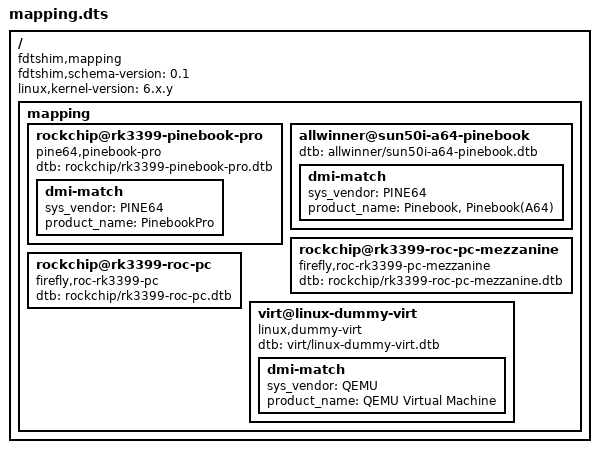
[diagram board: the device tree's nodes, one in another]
/dts-v1/;

/ {
	fdtshim,schema-version = "0.1";
	compatible = "fdtshim,mapping";
	linux,kernel-version = "6.x.y"; // metadata for convenience...
	// TODO: see what other metadata could be added...
	mapping {
		// Prop names are arbitrary, but should match the dtb path scheme.
		// `$vendor/$board.dtb` → `$vendor@$board`
		rockchip@rk3399-pinebook-pro {
			dtb = "rockchip/rk3399-pinebook-pro.dtb";
			// Compatible string should be the root compatible string of the device.
			// TODO: define what to do for devices with conflated compatible names.
			compatible = "pine64,pinebook-pro";
			dmi-match {
				// All of those entries would be good matches
				// The two first ones would be preferred and sufficient.
				sys_vendor = "PINE64";
				product_name = "PinebookPro";

			};
		};
		allwinner@sun50i-a64-pinebook {
			dtb = "allwinner/sun50i-a64-pinebook.dtb";
			// compatible = "pine64,pinebook"; // Commented-out for testing
			dmi-match {
				sys_vendor = "PINE64";
				// XXX multiple fields matching not supported yet!
				product_name = "Pinebook" // Vendor naming scheme
					, "Pinebook(A64)" // Tow-Boot naming scheme
				;
			};
		};
		rockchip@rk3399-roc-pc-mezzanine {
			// While it's not the case, if it also had `firefly,roc-rk3399-pc`
			// as an additional entry in `compatible`, it would need to be
			// listed first, or else the `firefly,roc-rk3399-pc` entry would
			// be matched here.
			dtb = "rockchip/rk3399-roc-pc-mezzanine.dtb";
			compatible = "firefly,roc-rk3399-pc-mezzanine";
		};
		rockchip@rk3399-roc-pc {
			dtb = "rockchip/rk3399-roc-pc.dtb";
			compatible = "firefly,roc-rk3399-pc";
		};
	};
};

// Test entries
/ {
	mapping {
		virt@linux-dummy-virt {
			dtb = "virt/linux-dummy-virt.dtb";
			compatible = "linux,dummy-virt";
			dmi-match {
				sys_vendor = "QEMU";
				product_name = "QEMU Virtual Machine";
				/*
				board_name = "";
				board_vendor = "";
				board_version = "";
				chassis_vendor = "QEMU";
				chassis_version = "";
				product_family = "";
				product_name = "QEMU Virtual Machine";
				product_sku = "";
				product_version = "virt-8.2";
				sys_vendor = "QEMU";
				*/
			};
		};
	};
};
